# PY32F001Bxx register map
Vendor: Puya; Series: PY32F0; File version: 1.0.0
CPU: CM0+ r0p1, little endian, no MPU, no FPU, 4 interrupt priority bits
Registers are 32-bit, read-write, reset 0x0 unless marked. A register's access mark holds for its fields unless they carry their own. Offsets are from the block's base; [hi:lo] are bit positions; {n}, {i} and the like mark numbered series.

## PWM
Base 0x40002800
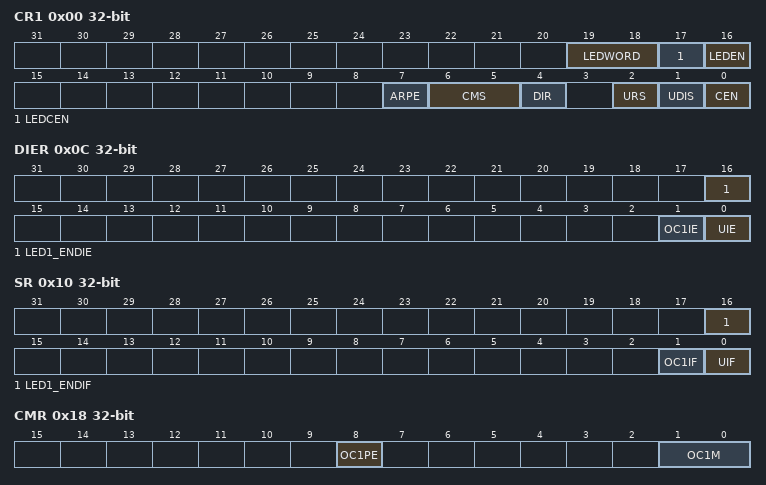
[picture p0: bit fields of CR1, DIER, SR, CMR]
0x00 CR1
  [19:18] LEDWORD, [17] LEDCEN, [16] LEDEN, [7] ARPE, [6:5] CMS, [4] DIR, [2] URS, [1] UDIS, [0] CEN
0x0C DIER
  [16] LED1_ENDIE, [1] OC1IE, [0] UIE
0x10 SR
  [16] LED1_ENDIF, [1] OC1IF, [0] UIF
0x14 EGR
  [0] UG
0x18 CMR
  [8] OC1PE, [1:0] OC1M
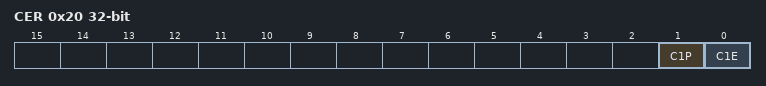
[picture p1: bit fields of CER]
0x20 CER
  [1] C1P, [0] C1E
0x24 CNT
  [9:0] CNT
0x28 PSC
  [7:0] PSC
0x2C ARR
  [9:0] ARR
0x34 CCR1
  [9:0] CCR1
0x50 LED1_DATA
  [23:0] LED1_DATA

## PWR — Power control
Base 0x40007000
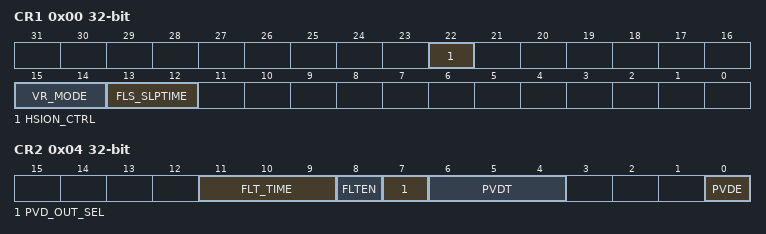
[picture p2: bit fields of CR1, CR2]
0x00 CR1 — Power control register 1
  [22] HSION_CTRL, [15:14] VR_MODE, [13:12] FLS_SLPTIME
0x04 CR2
  [11:9] FLT_TIME, [8] FLTEN, [7] PVD_OUT_SEL, [6:4] PVDT, [0] PVDE
0x10 SR
  [11] PVDO ro

## SYSCFG — System configuration controller
Base 0x40010000
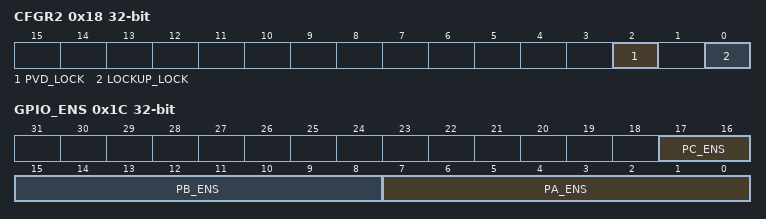
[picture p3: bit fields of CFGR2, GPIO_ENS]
0x18 CFGR2 — SYSCFG configuration register 2
  [2] PVD_LOCK — PVD LOCK selection
  [0] LOCKUP_LOCK — Cortex-M0+ LOCKUP bit enable bit
0x1C GPIO_ENS
  [17:16] PC_ENS, [15:8] PB_ENS, [7:0] PA_ENS

## TIM1 — Advanced timer
Base 0x40012C00
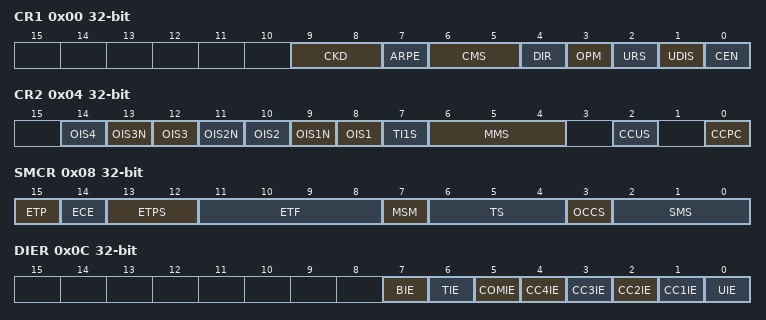
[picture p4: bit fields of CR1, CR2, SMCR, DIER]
0x00 CR1
  [9:8] CKD, [7] ARPE, [6:5] CMS, [4] DIR, [3] OPM, [2] URS, [1] UDIS, [0] CEN
0x04 CR2
  [2n+6] OIS{n} (n=1..4), [13] OIS3N, [11] OIS2N, [9] OIS1N, [7] TI1S, [6:4] MMS, [2] CCUS, [0] CCPC
0x08 SMCR
  [15] ETP, [14] ECE, [13:12] ETPS, [11:8] ETF, [7] MSM, [6:4] TS, [3] OCCS, [2:0] SMS
0x0C DIER
  [7] BIE, [6] TIE, [5] COMIE, [n] CC{n}IE (n=1..4), [0] UIE
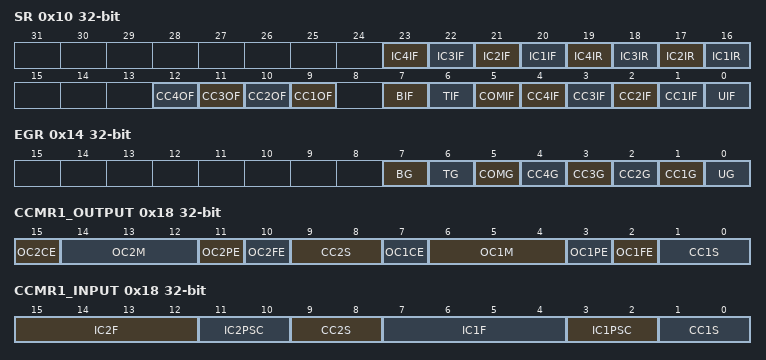
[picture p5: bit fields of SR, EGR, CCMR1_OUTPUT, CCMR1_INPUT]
0x10 SR
  [23] IC4IF — desc IC3IF
  [22] IC3IF
  [21] IC2IF
  [20] IC1IF
  [19] IC4IR — desc IC3IR
  [18] IC3IR
  [17] IC2IR
  [16] IC1IR
  [n+8] CC{n}OF (n=1..4)
  [7] BIF
  [6] TIF
  [5] COMIF
  [n] CC{n}IF (n=1..4)
  [0] UIF
0x14 EGR
  [7] BG
  [6] TG
  [5] COMG
  [4] CC4G
  [3] CC3G
  [2] CC2G
  [1] CC1G — Capture/Compare 1 Generation
  [0] UG
0x18 CCMR1_OUTPUT
  [15] OC2CE, [14:12] OC2M, [11] OC2PE, [10] OC2FE, [9:8] CC2S, [7] OC1CE, [6:4] OC1M, [3] OC1PE, [2] OC1FE, [1:0] CC1S
0x18 CCMR1_INPUT (alternate view of CCMR1_OUTPUT)
  [15:12] IC2F, [11:10] IC2PSC, [9:8] CC2S, [7:4] IC1F, [3:2] IC1PSC, [1:0] CC1S
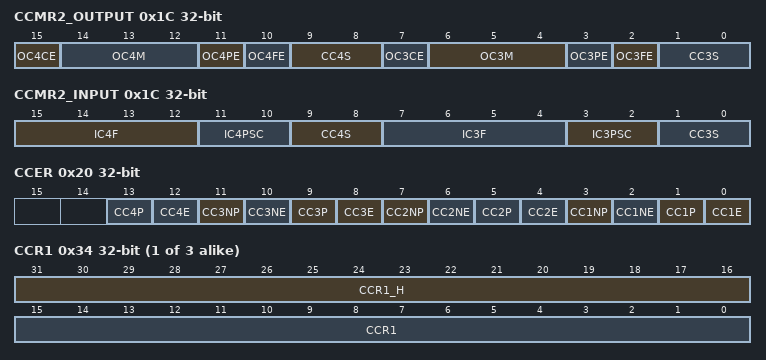
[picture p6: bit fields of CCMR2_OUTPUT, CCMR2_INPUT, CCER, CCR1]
0x1C CCMR2_OUTPUT
  [15] OC4CE, [14:12] OC4M, [11] OC4PE, [10] OC4FE, [9:8] CC4S, [7] OC3CE, [6:4] OC3M, [3] OC3PE, [2] OC3FE, [1:0] CC3S
0x1C CCMR2_INPUT (alternate view of CCMR2_OUTPUT)
  [15:12] IC4F, [11:10] IC4PSC, [9:8] CC4S, [7:4] IC3F, [3:2] IC3PSC, [1:0] CC3S
0x20 CCER
  [4n-3] CC{n}P (n=1..4), [4n-4] CC{n}E (n=1..4), [11] CC3NP, [10] CC3NE, [7] CC2NP, [6] CC2NE, [3] CC1NP, [2] CC1NE
0x24 CNT
  [15:0] CNT
0x28 PSC
  [15:0] PSC
0x2C ARR
  [15:0] ARR
0x30 RCR
  [7:0] REP
{0x30+4i} CCR{i} (i=1..3)
  [31:16] CCR{i}_H, [15:0] CCR{i}
0x40 CCR4
  [15:0] CCR4
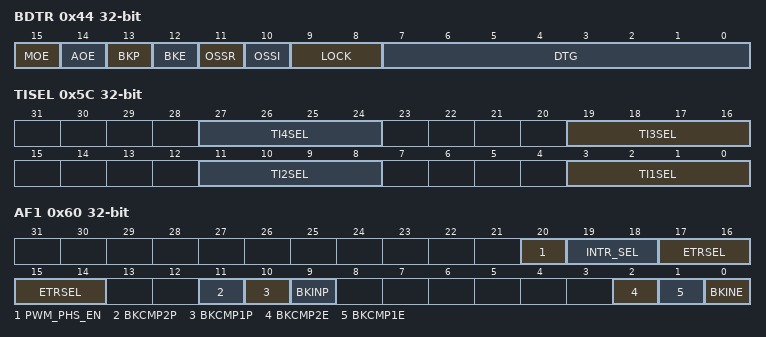
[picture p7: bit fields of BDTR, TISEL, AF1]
0x44 BDTR
  [15] MOE, [14] AOE, [13] BKP, [12] BKE, [11] OSSR, [10] OSSI, [9:8] LOCK, [7:0] DTG
0x5C TISEL
  [8n-5:8n-8] TI{n}SEL (n=1..4)
0x60 AF1
  [20] PWM_PHS_EN, [19:18] INTR_SEL, [17:14] ETRSEL, [11] BKCMP2P, [10] BKCMP1P, [9] BKINP, [2] BKCMP2E, [1] BKCMP1E, [0] BKINE
0x64 AF2
  [18:16] OCRSEL

## TIM14
Base 0x40002400
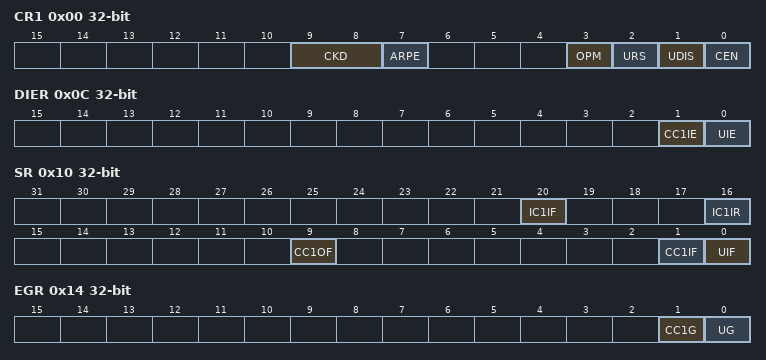
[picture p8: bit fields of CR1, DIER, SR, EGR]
0x00 CR1
  [9:8] CKD, [7] ARPE, [3] OPM, [2] URS, [1] UDIS, [0] CEN
0x0C DIER
  [1] CC1IE, [0] UIE
0x10 SR
  [20] IC1IF, [16] IC1IR, [9] CC1OF, [1] CC1IF, [0] UIF
0x14 EGR
  [1] CC1G — Capture/Compare 1 Generation
  [0] UG
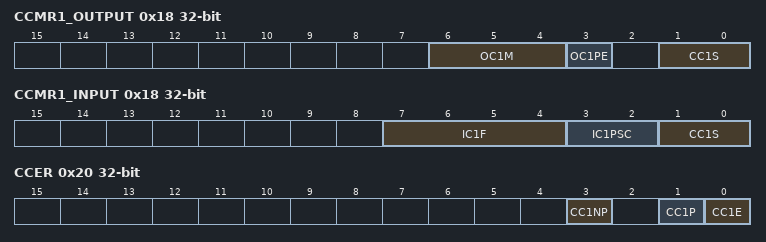
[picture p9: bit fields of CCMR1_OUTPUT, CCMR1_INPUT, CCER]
0x18 CCMR1_OUTPUT
  [6:4] OC1M, [3] OC1PE, [1:0] CC1S
0x18 CCMR1_INPUT (alternate view of CCMR1_OUTPUT)
  [7:4] IC1F, [3:2] IC1PSC, [1:0] CC1S
0x20 CCER
  [3] CC1NP, [1] CC1P, [0] CC1E
0x24 CNT
  [15:0] CNT
0x28 PSC
  [15:0] PSC
0x2C ARR
  [15:0] ARR
0x34 CCR1
  [15:0] CCR1
0x5C TISEL
  [3:0] TI1SEL

## UART1
Base 0x40004800
0x00 DR
  [8:0] DR — Receive/send data register
0x04 BRR
  [15:0] BRR — Baud rate register
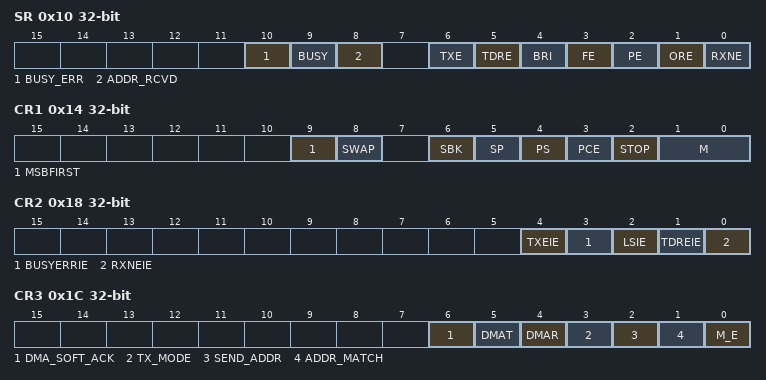
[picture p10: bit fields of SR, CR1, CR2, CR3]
0x10 SR
  [10] BUSY_ERR — Busy Detect Error
  [9] BUSY ro — UART Busy
  [8] ADDR_RCVD — Address Received Bit
  [6] TXE ro — Transmitter Empty bit
  [5] TDRE ro — Transmit Holding Register Empty bit
  [4] BRI — Break Interrupt bit
  [3] FE — Framing Error bit
  [2] PE — Parity Error bit
  [1] ORE — Overrun error bit
  [0] RXNE ro — Receive register not empty
0x14 CR1
  [9] MSBFIRST — MSB first mode
  [8] SWAP — TX/RX pin swap
  [6] SBK — Send Break
  [5] SP — Stick Parity
  [4] PS — Even Parity Select
  [3] PCE — Parity Enable
  [2] STOP — Number of stop bits
  [1:0] M — Data Length Select
0x18 CR2
  [4] TXEIE — Enable tx empty interruption
  [3] BUSYERRIE — Enable Busyerr state interruption
  [2] LSIE — Enable Receiver Line Status Interrupt
  [1] TDREIE — Enable Transmit Holding Register Empty Interrupt
  [0] RXNEIE — Enable Received Data Available Interrupt
0x1C CR3
  [6] DMA_SOFT_ACK — DMA software ack
  [5] DMAT — DMA transmit enable
  [4] DMAR — DMA receive enable
  [3] TX_MODE — Transmit mode control bit
  [2] SEND_ADDR — Send address control bit
  [1] ADDR_MATCH — Address Match Mode
  [0] M_E — Extension for DLS
0x20 RAR
  [7:0] RAR — Receive address matching register
0x24 TAR
  [7:0] TAR — Transmit address matching register
0x28 BRRF
  [3:0] BRRF — Baud rate fractional register

## VREF
Base 0x40010100
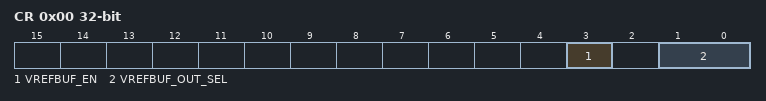
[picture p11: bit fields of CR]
0x00 CR
  [3] VREFBUF_EN, [1:0] VREFBUF_OUT_SEL
